# CC2340R5 register map
File version: 1.0
CPU: CM0P 1.0, other endian, MPU, FPU, 3 interrupt priority bits
Registers are 32-bit, read-write, reset 0x0 unless marked. A register's access mark holds for its fields unless they carry their own. Offsets are from the block's base; [hi:lo] are bit positions; lines under a group give offsets from that group; {n}, {i} and the like mark numbered series; 'fields as' and 'values as' point back to an identical list.

## GPIO — MCU GPIO - I/F for controlling and reading IO status and IO event status
Base 0x40023000
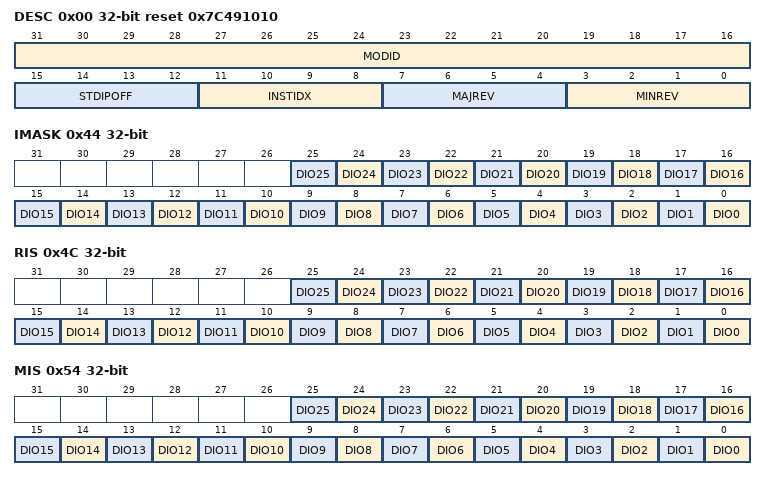
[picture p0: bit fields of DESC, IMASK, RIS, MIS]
0x00 DESC reset 0x7C491010 — Provides module ID, revision information, instance index
  [31:16] MODID ro — [31:16] Module identifier
    0xFFFF=MAXIMUM (Highest possible value); 0=MINIMUM (Smallest value)
  [15:12] STDIPOFF ro — [15:12] 0: STDIP MMRs do not exist 1:15: These MMRs begin at offset 64*STDIPOFF from IP base address
    15=MAXIMUM (Highest possible value); 0=MINIMUM (Smallest value)
  [11:8] INSTIDX ro — [11:8] If multiple instances of IP exists in SOC, this field can identify the instance number 0-15
    values as STDIPOFF
  [7:4] MAJREV ro — [7:4] Major revision version of IP
    values as STDIPOFF
  [3:0] MINREV ro — [3:0] Minor revision version of IP
    values as STDIPOFF
0x04 DESCEX reset 0x19 — Provide IP-specific instance information
  [5:0] NUMDIO ro — [5:0] This provides the total number of DIOs supported by GPIO. The number of DIOs supprted is NUMDIO + 1
    63=MAXIMUM (Highest possible value); 0=MINIMUM (Smallest value)
0x44 IMASK — Interrupt mask for DIO pins
  [all] fields
    1=SET (Set Interrrupt Mask); 0=CLR (Clear Interrupt Mask)
  [n] DIO{n} (n=0..25) — [{n}:{n}] Interrupt mask for DIO{n}
0x4C RIS — Raw interrupt flag for DIO pins
  [all] fields
    1=SET (Interrupt occured); 0=CLR (Interrupt did not occur)
  [n] DIO{n} ro (n=0..25) — [{n}:{n}] Raw interrupt flag for DIO{n}
0x54 MIS — Masked interrupt flag for DIO pins
  [all] fields
    1=SET (Interrupt occured); 0=CLR (Interrupt did not occur)
  [n] DIO{n} ro (n=0..25) — [{n}:{n}] Masked interrupt flag for DIO{n}
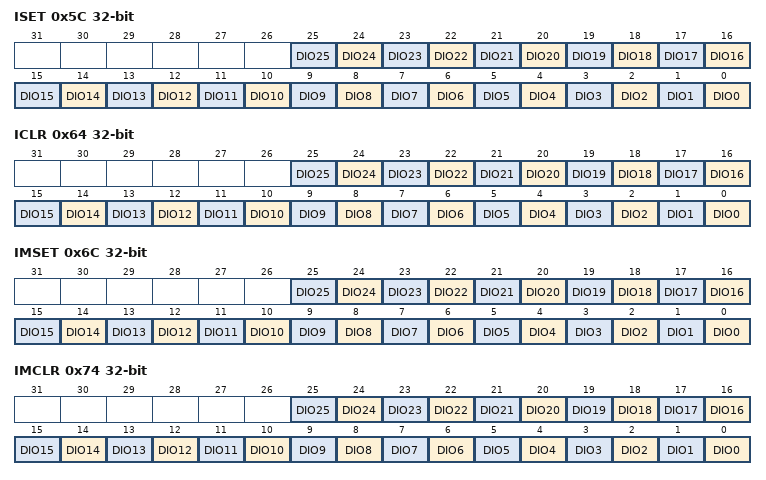
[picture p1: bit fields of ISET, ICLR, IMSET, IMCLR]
0x5C ISET — Set interrupt flag in RIS by writing a one
  [all] fields
    1=SET (Set Interrupt); 0=NO_EFFECT (Writing 0 has no effect)
  [n] DIO{n} wo (n=0..25) — [{n}:{n}] Set DIO{n} in RIS
0x64 ICLR — Clear interrupt flag in RIS by writing a one
  [all] fields
    1=CLR (Clear Interrupt); 0=NO_EFFECT (Writing 0 has no effect)
  [n] DIO{n} wo (n=0..25) — [{n}:{n}] Clears DIO{n} in RIS
0x6C IMSET — Set interrupt mask in IMASK by writing a one
  [all] fields
    1=SET (Set interrupt mask); 0=NO_EFFECT (Writing 0 has no effect)
  [n] DIO{n} wo (n=0..25) — [{n}:{n}] Sets DIO{n} in IMASK
0x74 IMCLR — Clear interrupt mask in IMASK by writing a one
  [all] fields
    1=CLR (Clear interrupt mask); 0=NO_EFFECT (Writing 0 has no effect)
  [n] DIO{n} wo (n=0..25) — [{n}:{n}] Clears DIO{n} in IMASK
0x7C DTB — Digital test bus mux selection
  [2:0] SEL — [2:0] DTB MUX select pin value
    {v}=GRP{v} (Selects test group {v}) (v=1..7); 0=DISABLE (DTB output from peripheral is 0x0.)
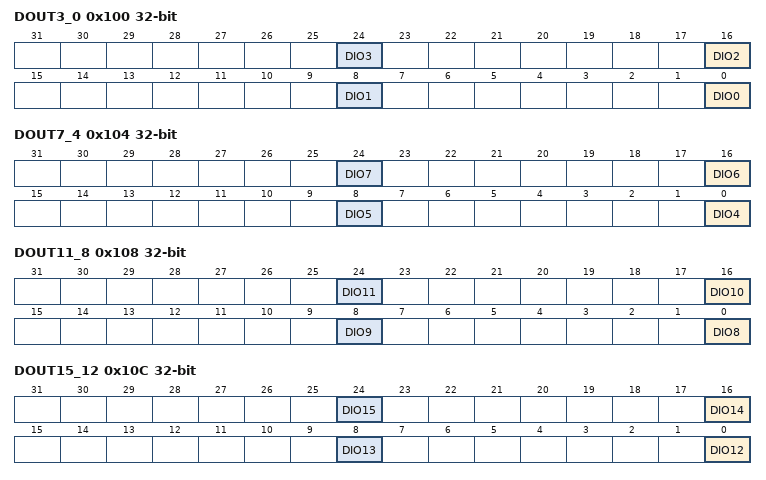
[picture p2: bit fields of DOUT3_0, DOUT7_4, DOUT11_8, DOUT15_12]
0x100 DOUT3_0 — Data out 3 to 0. Alias register for byte access to DOUT31_0[3:0] bits.
  [all] fields
    1=ONE (Output is set to 1); 0=ZERO (Output is set to 0)
  [8n] DIO{n} (n=0..3) — [{8n}:{8n}] Data output for DIO{n}
0x104 DOUT7_4 — Data out 7 to 4. Alias register for byte access to DOUT31_0[7:4] bits.
  [all] fields
    1=ONE (Output is set to 1); 0=ZERO (Output is set to 0)
  [8n-32] DIO{n} (n=4..7) — [{8n-32}:{8n-32}] Data output for DIO{n}
0x108 DOUT11_8 — Data out 11 to 8. Alias register for byte access to DOUT31_0[11:8] bits.
  [all] fields
    1=ONE (Output is set to 1); 0=ZERO (Output is set to 0)
  [8n-64] DIO{n} (n=8..11) — [{8n-64}:{8n-64}] Data output for DIO{n}
0x10C DOUT15_12 — Data out 15 to 12. Alias register for byte access to DOUT31_0[15:12] bits.
  [all] fields
    1=ONE (Output is set to 1); 0=ZERO (Output is set to 0)
  [8n-96] DIO{n} (n=12..15) — [{8n-96}:{8n-96}] Data output for DIO{n}
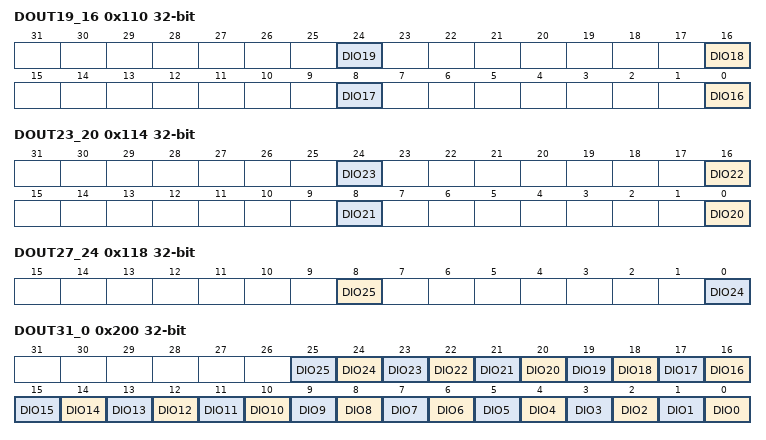
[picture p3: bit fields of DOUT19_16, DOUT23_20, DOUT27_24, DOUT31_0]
0x110 DOUT19_16 — Data out 19 to 16. Alias register for byte access to DOUT31_0[19:16] bits.
  [all] fields
    1=ONE (Output is set to 1); 0=ZERO (Output is set to 0)
  [8n-128] DIO{n} (n=16..19) — [{8n-128}:{8n-128}] Data output for DIO{n}
0x114 DOUT23_20 — Data out 23 to 20. Alias register for byte access to DOUT31_0[23:20] bits.
  [all] fields
    1=ONE (Output is set to 1); 0=ZERO (Output is set to 0)
  [8n-160] DIO{n} (n=20..23) — [{8n-160}:{8n-160}] Data output for DIO{n}
0x118 DOUT27_24 — Data out 27 to 24. Alias register for byte access to DOUT31_0[27:24] bits.
  [8] DIO25 — [8:8] Data output for DIO25
    1=ONE (Output is set to 1); 0=ZERO (Output is set to 0)
  [0] DIO24 — [0:0] Data output for DIO24
    1=ONE (Output is set to 1); 0=ZERO (Output is set to 0)
0x200 DOUT31_0 — Data Output for DIO 31 to 0 pins.
  [all] fields
    1=ONE (Output is set to 1); 0=ZERO (Output is set to 0)
  [n] DIO{n} (n=0..25) — [{n}:{n}] Data output for DIO{n}
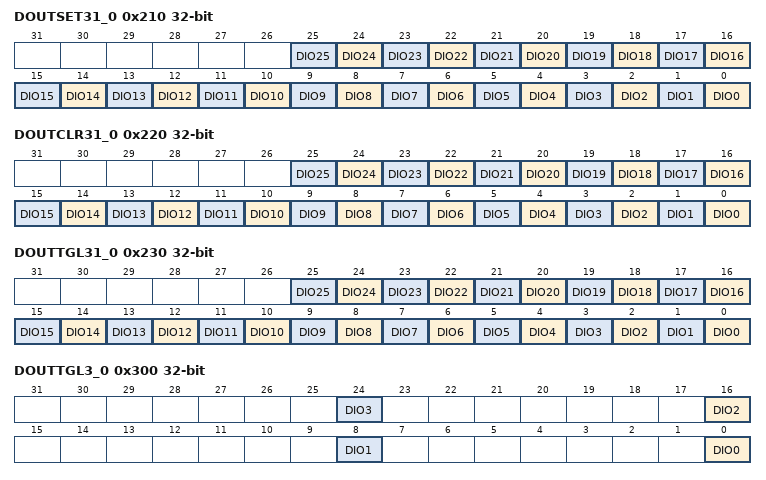
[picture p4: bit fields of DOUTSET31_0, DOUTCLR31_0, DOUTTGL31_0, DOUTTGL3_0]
0x210 DOUTSET31_0 — Data output set for DIO 31 to 0 pins. Writing 1 to a bit position sets the corresponding bit in the DOUT31_0 register.
  [all] fields
    1=SET; 0=NO_EFFECT
  [n] DIO{n} wo (n=0..25) — [{n}:{n}] Set bit DIO{n} in DOUT31_0
0x220 DOUTCLR31_0 — Data output clear for DIO 31 to 0 pins. Writing 1 to a bit position clears the corresponding bit in the DOUT31_0 register.
  [all] fields
    1=CLR (Clear); 0=NO_EFFECT
  [n] DIO{n} wo (n=0..25) — [{n}:{n}] Clear bit DIO{n} in DOUT31_0
0x230 DOUTTGL31_0 — Data output toggle for DIO 31 to 0 pins. Writing 1 to a bit position will invert the corresponding bit in DOUT31_0 register.
  [all] fields
    1=TOGGLE; 0=NO_EFFECT
  [n] DIO{n} wo (n=0..25) — [{n}:{n}] Toggles bit DIO{n} in DOUT31_0
0x300 DOUTTGL3_0 — Data out toggle 3 to 0. Alias register for byte access to DOUTTGL31_0[3:0] bits.
  [all] fields
    1=TOGGLE; 0=NO_EFFECT
  [8n] DIO{n} wo (n=0..3) — [{8n}:{8n}] Data output toggle for DIO{n}
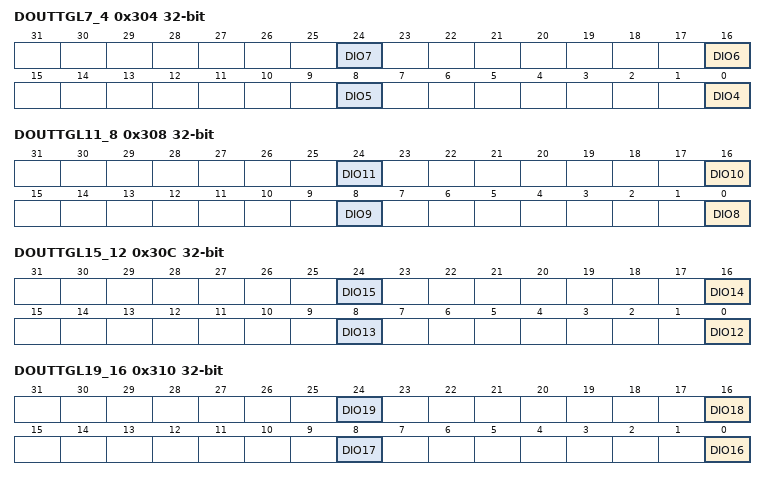
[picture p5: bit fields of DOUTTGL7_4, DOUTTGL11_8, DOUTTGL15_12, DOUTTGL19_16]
0x304 DOUTTGL7_4 — Data out toggle 7 to 4. Alias register for byte access to DOUTTGL31_0[7:4] bits.
  [all] fields
    1=TOGGLE; 0=NO_EFFECT
  [8n-32] DIO{n} wo (n=4..7) — [{8n-32}:{8n-32}] Data output toggle for DIO{n}
0x308 DOUTTGL11_8 — Data out toggle 11 to 8. Alias register for byte access to DOUTTGL31_0[11:8] bits.
  [all] fields
    1=TOGGLE; 0=NO_EFFECT
  [8n-64] DIO{n} wo (n=8..11) — [{8n-64}:{8n-64}] Data output toggle for DIO{n}
0x30C DOUTTGL15_12 — Data out toggle 15 to 12. Alias register for byte access to DOUTTGL31_0[15:12] bits.
  [all] fields
    1=TOGGLE; 0=NO_EFFECT
  [8n-96] DIO{n} wo (n=12..15) — [{8n-96}:{8n-96}] Data output toggle for DIO{n}
0x310 DOUTTGL19_16 — Data out toggle 19 to 16. Alias register for byte access to DOUTTGL31_0[19:16] bits.
  [all] fields
    1=TOGGLE; 0=NO_EFFECT
  [8n-128] DIO{n} wo (n=16..19) — [{8n-128}:{8n-128}] Data output toggle for DIO{n}
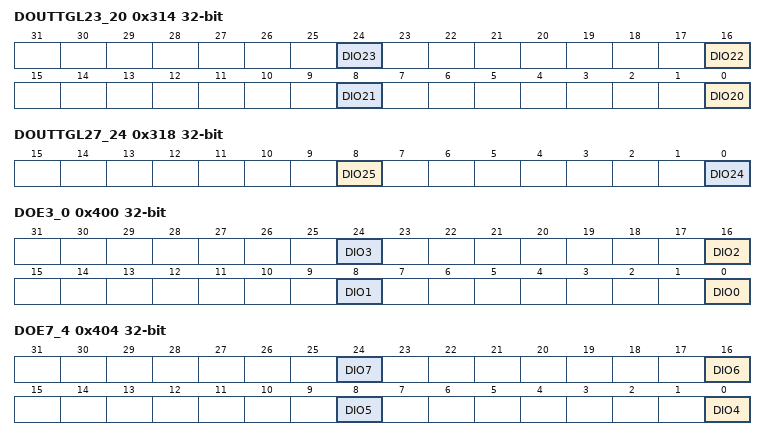
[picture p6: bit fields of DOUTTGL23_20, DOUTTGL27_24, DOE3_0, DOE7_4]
0x314 DOUTTGL23_20 — Data out toggle 23 to 20. Alias register for byte access to DOUTTGL31_0[23:20] bits.
  [all] fields
    1=TOGGLE; 0=NO_EFFECT
  [8n-160] DIO{n} wo (n=20..23) — [{8n-160}:{8n-160}] Data output toggle for DIO{n}
0x318 DOUTTGL27_24 — Data out toggle 27 to 24. Alias register for byte access to DOUTTGL31_0[27:24] bits.
  [8] DIO25 wo — [8:8] Data output toggle for DIO25
    1=TOGGLE; 0=NO_EFFECT
  [0] DIO24 wo — [0:0] Data output toggle for DIO24
    1=TOGGLE; 0=NO_EFFECT
0x400 DOE3_0 — Data out enable 3 to 0. Alias register for byte access to DOE31_0[3:0] bits.
  [all] fields
    1=ENABLE (Output enabled); 0=DISABLE (Output disabled)
  [8n] DIO{n} (n=0..3) — [{8n}:{8n}] Data output enable for DIO{n}
0x404 DOE7_4 — Data out enable 7 to 4. Alias register for byte access to DOE31_0[7:4] bits.
  [all] fields
    1=ENABLE (Output enabled); 0=DISABLE (Output disabled)
  [8n-32] DIO{n} (n=4..7) — [{8n-32}:{8n-32}] Data output enable for DIO{n}
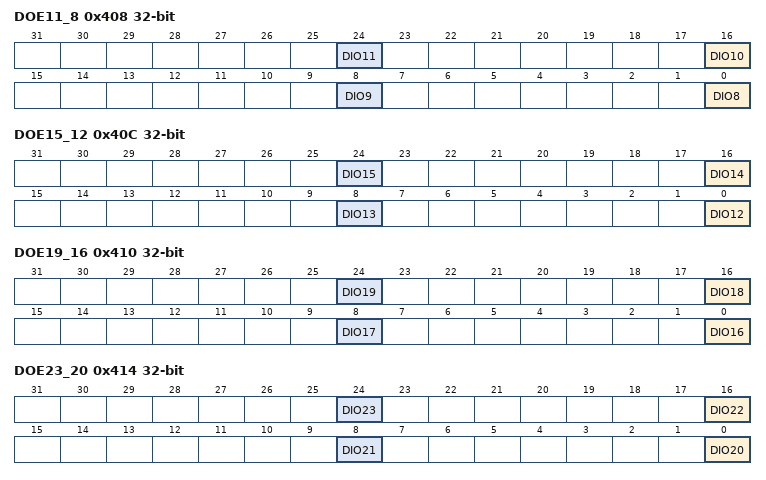
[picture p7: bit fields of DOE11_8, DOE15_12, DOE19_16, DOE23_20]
0x408 DOE11_8 — Data out enable 11 to 8. Alias register for byte access to DOE31_0[11:8] bits.
  [all] fields
    1=ENABLE (Output enabled); 0=DISABLE (Output disabled)
  [8n-64] DIO{n} (n=8..11) — [{8n-64}:{8n-64}] Data output enable for DIO{n}
0x40C DOE15_12 — Data out enable 15 to 12. Alias register for byte access to DOE31_0[15:12] bits.
  [all] fields
    1=ENABLE (Output enabled); 0=DISABLE (Output disabled)
  [8n-96] DIO{n} (n=12..15) — [{8n-96}:{8n-96}] Data output enable for DIO{n}
0x410 DOE19_16 — Data out enable 19 to 16. Alias register for byte access to DOE31_0[19:16] bits.
  [all] fields
    1=ENABLE (Output enabled); 0=DISABLE (Output disabled)
  [8n-128] DIO{n} (n=16..19) — [{8n-128}:{8n-128}] Data output enable for DIO{n}
0x414 DOE23_20 — Data out enable 23 to 20. Alias register for byte access to DOE31_0[23:20] bits.
  [all] fields
    1=ENABLE (Output enabled); 0=DISABLE (Output disabled)
  [8n-160] DIO{n} (n=20..23) — [{8n-160}:{8n-160}] Data output enable for DIO{n}
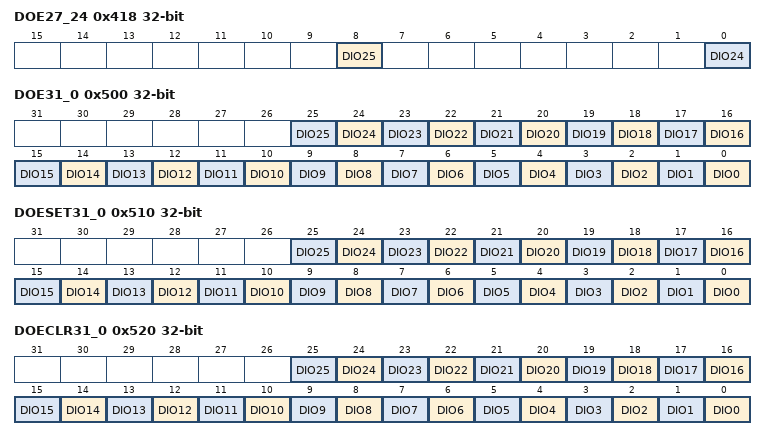
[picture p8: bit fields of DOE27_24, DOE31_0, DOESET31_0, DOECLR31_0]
0x418 DOE27_24 — Data out enable 27 to 24. Alias register for byte access to DOE31_0[27:24] bits.
  [8] DIO25 — [8:8] Data output enable for DIO25
    1=ENABLE (Output enabled); 0=DISABLE (Output disabled)
  [0] DIO24 — [0:0] Data output enable for DIO24
    1=ENABLE (Output enabled); 0=DISABLE (Output disabled)
0x500 DOE31_0 — Data output enable for DIO 31 to 0 pins.
  [all] fields
    1=ENABLE (Output enabled); 0=DISABLE (Output disabled)
  [n] DIO{n} (n=0..25) — [{n}:{n}] Data output enable for DIO{n}
0x510 DOESET31_0 — Data output enable set for DIO 31 to 0 pins. Writing 1 to a bit position sets the corresponding bit in the DOE31_0 register.
  [all] fields
    1=SET; 0=NO_EFFECT
  [n] DIO{n} wo (n=0..25) — [{n}:{n}] Set bit DIO{n} in DOE31_0
0x520 DOECLR31_0 — Data output enable clear for DIO 31 to 0 pins. Writing 1 to a bit position clears the corresponding bit in the DOE31_0 register.
  [all] fields
    1=CLR (Clear); 0=NO_EFFECT
  [n] DIO{n} wo (n=0..25) — [{n}:{n}] Clears bit DIO{n} in DOE31_0
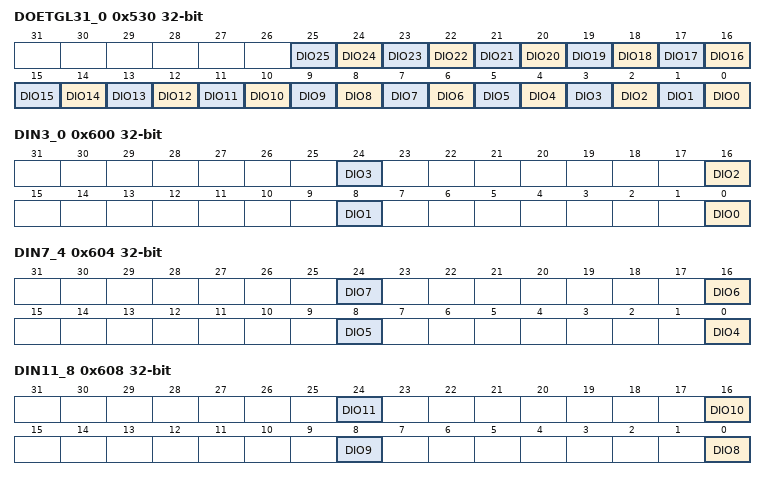
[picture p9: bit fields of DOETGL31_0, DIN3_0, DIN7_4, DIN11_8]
0x530 DOETGL31_0 — Data output enable toggle for DIO 31 to 0 pins. Writing 1 to a bit position will invert the corresponding bit in DOE31_0 register.
  [all] fields
    1=TOGGLE; 0=NO_EFFECT
  [n] DIO{n} wo (n=0..25) — [{n}:{n}] Toggles bit DIO{n} in DOE31_0
0x600 DIN3_0 — Data input 3 to 0. Alias register for byte access to DIN31_0[3:0] bits.
  [all] fields
    1=ONE (Input value is 1); 0=ZERO (Input value is 0)
  [8n] DIO{n} ro (n=0..3) — [{8n}:{8n}] Data input from DIO{n}
0x604 DIN7_4 — Data input 7 to 4. Alias register for byte access to DIN31_0[7:4] bits.
  [all] fields
    1=ONE (Input value is 1); 0=ZERO (Input value is 0)
  [8n-32] DIO{n} ro (n=4..7) — [{8n-32}:{8n-32}] Data input from DIO{n}
0x608 DIN11_8 — Data input 11 to 8. Alias register for byte access to DIN31_0[11:8] bits.
  [all] fields
    1=ONE (Input value is 1); 0=ZERO (Input value is 0)
  [8n-64] DIO{n} ro (n=8..11) — [{8n-64}:{8n-64}] Data input from DIO{n}
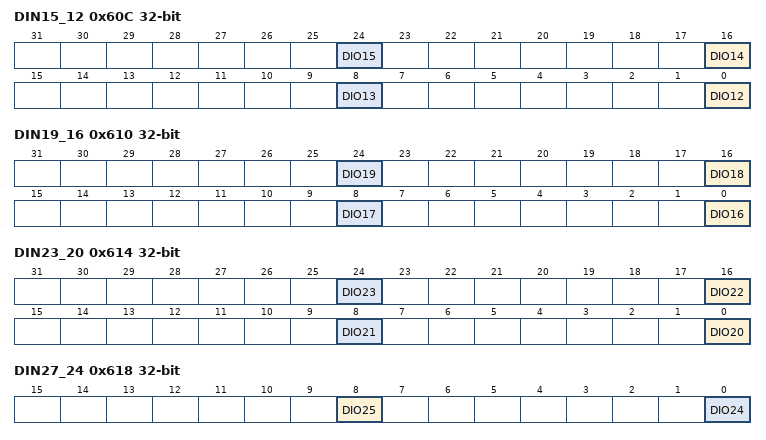
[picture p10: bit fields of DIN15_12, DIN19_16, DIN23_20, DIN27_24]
0x60C DIN15_12 — Data input 15 to 12. Alias register for byte access to DIN31_0[15:12] bits.
  [all] fields
    1=ONE (Input value is 1); 0=ZERO (Input value is 0)
  [8n-96] DIO{n} ro (n=12..15) — [{8n-96}:{8n-96}] Data input from DIO{n}
0x610 DIN19_16 — Data input 19 to 16. Alias register for byte access to DIN31_0[19:16] bits.
  [all] fields
    1=ONE (Input value is 1); 0=ZERO (Input value is 0)
  [8n-128] DIO{n} ro (n=16..19) — [{8n-128}:{8n-128}] Data input from DIO{n}
0x614 DIN23_20 — Data input 23 to 20. Alias register for byte access to DIN31_0[23:20] bits.
  [all] fields
    1=ONE (Input value is 1); 0=ZERO (Input value is 0)
  [8n-160] DIO{n} ro (n=20..23) — [{8n-160}:{8n-160}] Data input from DIO{n}
0x618 DIN27_24 — Data input 27 to 24. Alias register for byte access to DIN31_0[27:24] bits.
  [8] DIO25 ro — [8:8] Data input from DIO25
    1=ONE (Input value is 1); 0=ZERO (Input value is 0)
  [0] DIO24 ro — [0:0] Data input from DIO24
    1=ONE (Input value is 1); 0=ZERO (Input value is 0)
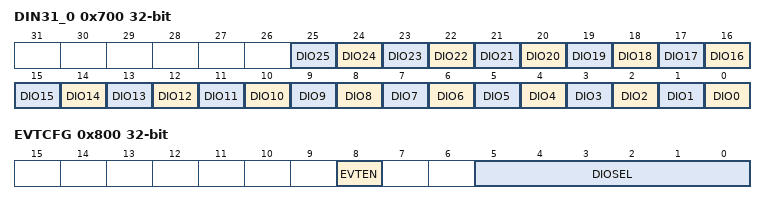
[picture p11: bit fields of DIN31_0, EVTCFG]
0x700 DIN31_0 — Data input from DIO 31 to 0 pins.
  [all] fields
    1=ONE (Input value is 1); 0=ZERO (Input value is 0)
  [n] DIO{n} ro (n=0..25) — [{n}:{n}] Data input from DIO{n}
0x800 EVTCFG — Event configuration. This register is used to select DIO for GPIO to publish event on SVT event fabric. It also contains enable bit that is used to mask the event.
  [8] EVTEN — [8:8] Enables GPIO to publish edge qualified selected DIO event on SVT event fabric. Design note: The edge detector flop is cleared automatically for the selected DIO once the event is published.
    1=ENABLE; 0=DISABLE
  [5:0] DIOSEL — [5:0] This is used to select DIO for event generation. For example, DIOSEL = 0x0 selects DIO0 and DIOSEL = 0x8 selects DIO8.
    63=MAXIMUM (Maximum value); 0=MINIMUM (Minimum value)
